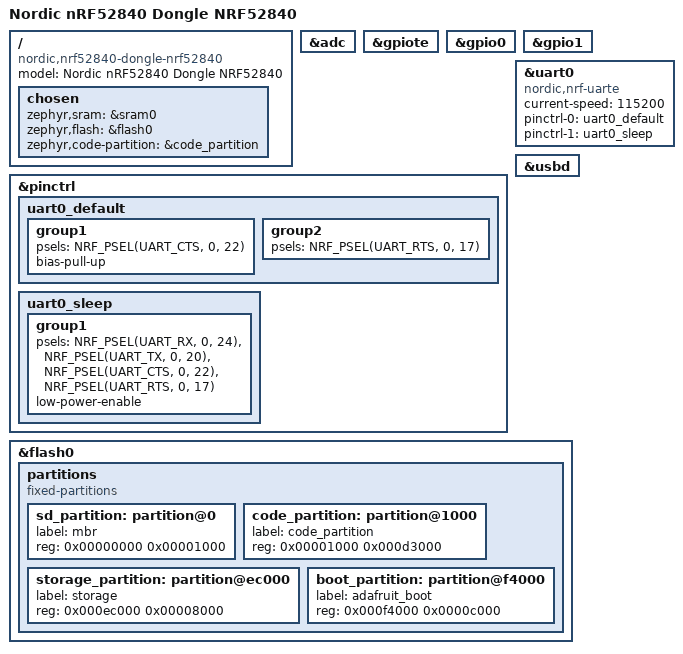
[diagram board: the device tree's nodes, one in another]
/*
 * Copyright (c) 2018 Nordic Semiconductor ASA
 * Copyright (c) 2017 Linaro Limited
 *
 * SPDX-License-Identifier: Apache-2.0
 */

/dts-v1/;
#include <nordic/nrf52840_qiaa.dtsi>

/ {
  model = "Nordic nRF52840 Dongle NRF52840";
  compatible = "nordic,nrf52840-dongle-nrf52840";

  chosen {
    zephyr,sram = &sram0;
    zephyr,flash = &flash0;
    zephyr,code-partition = &code_partition;
  };
};

&adc {
  status = "okay";
};

&gpiote {
  status = "okay";
};

&gpio0 {
  status = "okay";
};

&gpio1 {
  status = "okay";
};

&pinctrl {
    uart0_default: uart0_default {
        group1 {
            psels = <NRF_PSEL(UART_RX, 0, 24)>;
            psels = <NRF_PSEL(UART_CTS, 0, 22)>;
            bias-pull-up;
        };
        group2 {
            psels = <NRF_PSEL(UART_TX, 0, 20)>;
            psels = <NRF_PSEL(UART_RTS, 0, 17)>;
        };
    };

    uart0_sleep: uart0_sleep {
        group1 {
            psels = <NRF_PSEL(UART_RX, 0, 24)>,
                    <NRF_PSEL(UART_TX, 0, 20)>,
                    <NRF_PSEL(UART_CTS, 0, 22)>,
                    <NRF_PSEL(UART_RTS, 0, 17)>;
            low-power-enable;
        };
    };
};

&uart0 {
  compatible = "nordic,nrf-uarte";
  status = "okay";
  current-speed = <115200>;
  pinctrl-0 = <&uart0_default>;
  pinctrl-1 = <&uart0_sleep>;
  pinctrl-names = "default", "sleep";
};

zephyr_udc0: &usbd {
    status = "okay";
};

&flash0 {
        /*
        * For more information, see:
        * http://docs.zephyrproject.org/latest/devices/dts/flash_partitions.html
        */
        partitions {
                compatible = "fixed-partitions";
                #address-cells = <1>;
                #size-cells = <1>;

                sd_partition: partition@0 {
                        label = "mbr";
                        reg = <0x00000000 0x00001000>;
                };
                code_partition: partition@1000 {
                        label = "code_partition";
                        reg = <0x00001000 0x000d3000>;
                };

                /*
                * The flash starting at 0x000ec000 and ending at
                * 0x000f3fff is reserved for use by the application.
                */

                /*
                * Storage partition will be used by FCB/LittleFS/NVS
                * if enabled.
                */
                storage_partition: partition@ec000 {
                        label = "storage";
                        reg = <0x000ec000 0x00008000>;
                };

                boot_partition: partition@f4000 {
                       label = "adafruit_boot";
                       reg = <0x000f4000 0x0000c000>;
               };
       };
};
